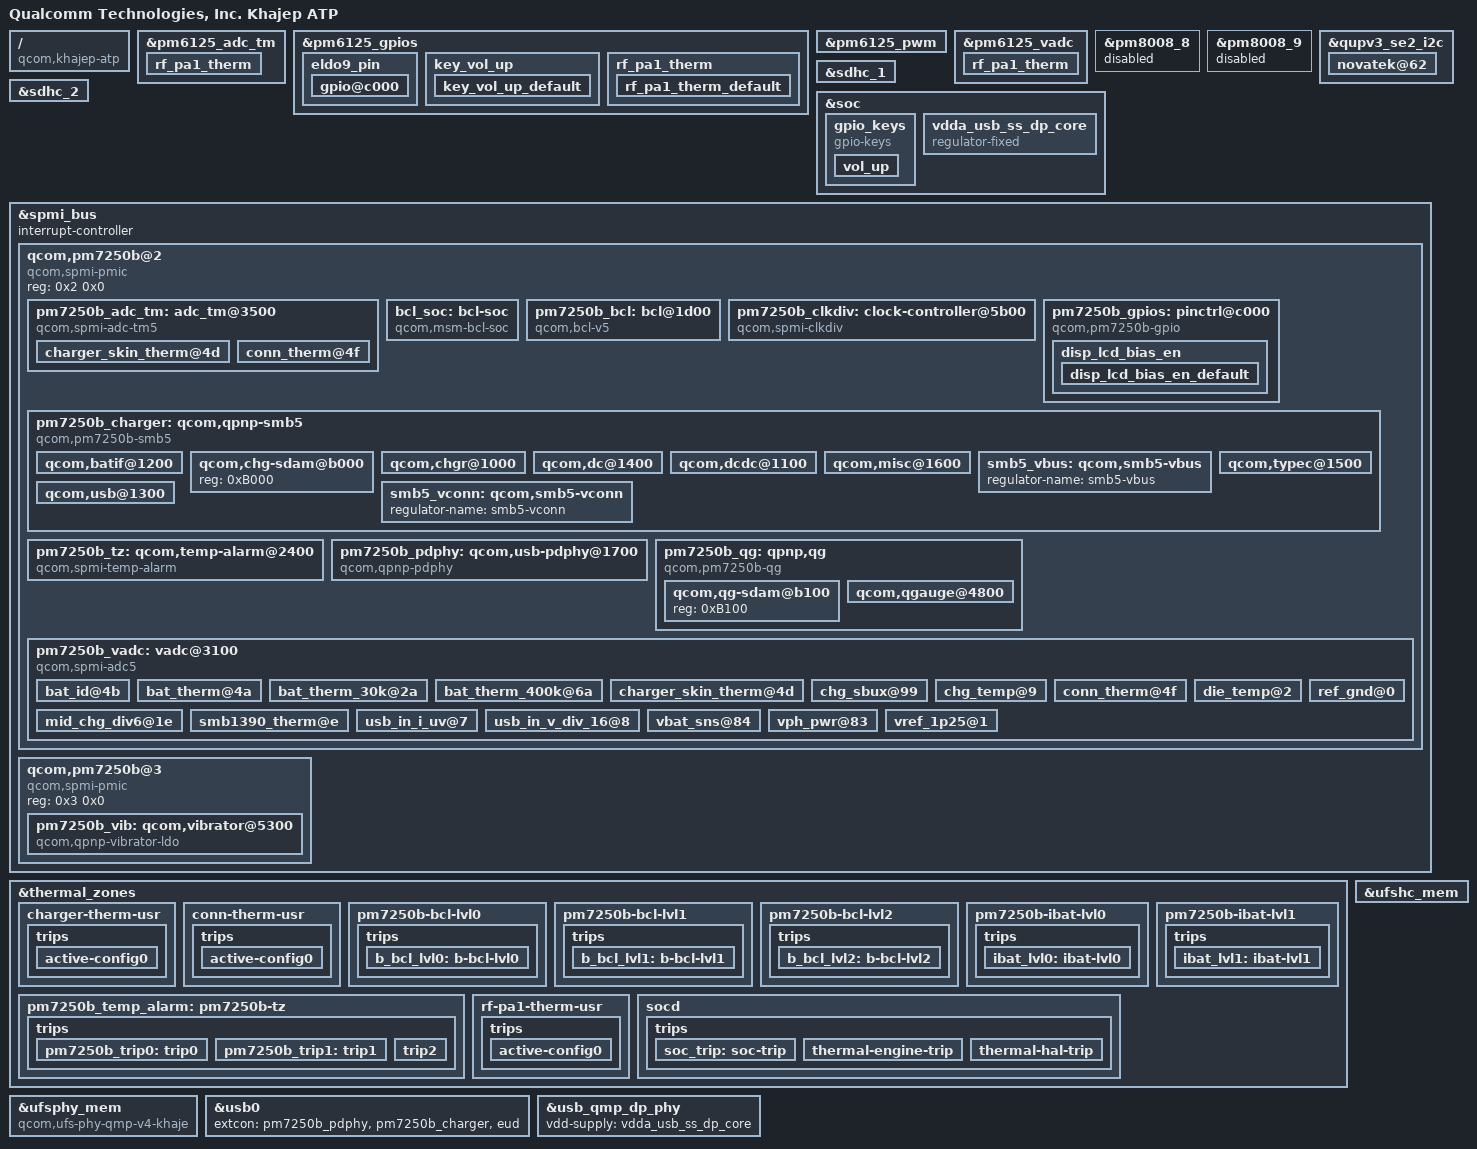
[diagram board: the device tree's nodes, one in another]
/dts-v1/;

/ {
    compatible = "qcom,khajep-atp", "qcom,khajep", "qcom,atp";
    model = "Qualcomm Technologies, Inc. Khajep ATP";
    qcom,board-id = <0x21 0x0>;
    qcom,msm-id = <0x231 0x10000>;
    qcom,pmic-id = <0x2D 0x2E 0x0 0x0>;
};

&pm6125_adc_tm {
    status = "ok";
    rf_pa1_therm {
        io-channels = <&pm6125_vadc 0x55>;
        qcom,hw-settle-time-us = <0xC8>;
        qcom,ratiometric;
        reg = <0x3>;
    };
};

&pm6125_gpios {
    eldo9_pin {
        gpio@c000 {
            bias-disable;
            function = "normal";
            output-high;
            pins = "gpio1";
            power-source = <0x0>;
            qcom,drive-strength = <0x2>;
        };
    };
    key_vol_up {
        key_vol_up_default: key_vol_up_default {
            bias-pull-up;
            function = "normal";
            input-enable;
            pins = "gpio5";
            power-source = <0x0>;
        };
    };
    rf_pa1_therm {
        rf_pa1_therm_default: rf_pa1_therm_default {
            bias-high-impedance;
            pins = "gpio7";
        };
    };
};

&pm6125_pwm {
    status = "okay";
};

&pm6125_vadc {
    pinctrl-0 = <&camera_therm_default &emmc_therm_default &rf_pa1_therm_default>;
    rf_pa1_therm {
        label = "rf_pa1_therm";
        qcom,hw-settle-time = <0xC8>;
        qcom,pre-scaling = <0x1 0x1>;
        qcom,ratiometric;
        reg = <0x55>;
    };
};

&pm8008_8 {
    status = "disabled";
};

&pm8008_9 {
    status = "disabled";
};

&qupv3_se2_i2c {
    status = "okay";
    novatek@62 {
        interrupt-parent = <&tlmm>;
        interrupts = <0x50 0x2008>;
        novatek,irq-gpio = <&tlmm 0x50 0x2008>;
        novatek,reset-gpio = <&tlmm 0x56 0x0>;
        pinctrl-0 = <&ts_int_active &ts_reset_active>;
        pinctrl-1 = <&ts_int_suspend &ts_reset_suspend>;
        pinctrl-2 = <&ts_release>;
        pinctrl-names = "pmx_ts_active", "pmx_ts_suspend", "pmx_ts_release";
        reg = <0x62>;
        status = "ok";
    };
};

&sdhc_1 {
    pinctrl-0 = <&sdc1_on>;
    pinctrl-1 = <&sdc1_off>;
    pinctrl-names = "active", "sleep";
    qcom,vdd-current-level = <0x0 0x8B290>;
    qcom,vdd-io-always-on;
    qcom,vdd-io-current-level = <0x0 0x4F588>;
    qcom,vdd-io-lpm-sup;
    qcom,vdd-io-voltage-level = <0x1B7740 0x1B7740>;
    qcom,vdd-voltage-level = <0x2D2A80 0x2D2A80>;
    status = "ok";
    vdd-io-supply = <&L11A>;
    vdd-supply = <&L24A>;
};

&sdhc_2 {
    cd-gpios = <&tlmm 0x58 0x1>;
    pinctrl-0 = <&sdc2_on>;
    pinctrl-1 = <&sdc2_off>;
    pinctrl-names = "active", "sleep";
    qcom,vdd-current-level = <0x0 0xC3500>;
    qcom,vdd-io-bias-current-level = <0x0 0x1770>;
    qcom,vdd-io-bias-voltage-level = <0x132A40 0x132A40>;
    qcom,vdd-io-current-level = <0x0 0x55F0>;
    qcom,vdd-io-voltage-level = <0x1B7740 0x2D2A80>;
    qcom,vdd-voltage-level = <0x2D2A80 0x2D2A80>;
    status = "ok";
    vdd-io-bias-supply = <&L7A>;
    vdd-io-supply = <&L5A>;
    vdd-supply = <&L22A>;
};

&soc {
    gpio_keys {
        compatible = "gpio-keys";
        label = "gpio-keys";
        pinctrl-0 = <&key_vol_up_default>;
        pinctrl-names = "default";
        vol_up {
            debounce-interval = <0xF>;
            gpio-key,wakeup;
            gpios = <&pm6125_gpios 0x5 0x1>;
            label = "volume_up";
            linux,can-disable;
            linux,code = <0x73>;
            linux,input-type = <0x1>;
        };
    };
    vdda_usb_ss_dp_core {
        compatible = "regulator-fixed";
        enable-active-high;
        gpio = <&pm6125_gpios 0x1 0x0>;
        pinctrl-0 = <&usb_eldo9>;
        pinctrl-names = "default";
        regulator-max-microvolt = <0xD6D80>;
        regulator-min-microvolt = <0xD6D80>;
        regulator-name = "vdd_supply";
    };
};

&spmi_bus {
    #address-cells = <0x2>;
    #interrupt-cells = <0x4>;
    #size-cells = <0x0>;
    interrupt-controller;
    qcom,pm7250b@2 {
        #address-cells = <0x1>;
        #size-cells = <0x0>;
        compatible = "qcom,spmi-pmic";
        reg = <0x2 0x0>;
        pm7250b_adc_tm: adc_tm@3500 {
            #address-cells = <0x1>;
            #size-cells = <0x0>;
            #thermal-sensor-cells = <0x1>;
            compatible = "qcom,spmi-adc-tm5";
            interrupt-names = "pm-adc-tm5";
            interrupts = <0x2 0x35 0x0 0x1>;
            reg = <0x3500>;
            status = "ok";
            charger_skin_therm@4d {
                io-channels = <&pm7250b_vadc 0x4D>;
                qcom,hw-settle-time-us = <0xC8>;
                qcom,ratiometric;
                reg = <0x0>;
            };
            conn_therm@4f {
                io-channels = <&pm7250b_vadc 0x4F>;
                qcom,hw-settle-time-us = <0xC8>;
                qcom,ratiometric;
                reg = <0x1>;
            };
        };
        bcl_soc: bcl-soc {
            #thermal-sensor-cells = <0x0>;
            compatible = "qcom,msm-bcl-soc";
        };
        pm7250b_bcl: bcl@1d00 {
            #thermal-sensor-cells = <0x1>;
            compatible = "qcom,bcl-v5";
            interrupt-names = "bcl-lvl0", "bcl-lvl1", "bcl-lvl2";
            interrupts = <0x2 0x1D 0x0 0x0 0x2 0x1D 0x1 0x0 0x2 0x1D 0x2 0x0>;
            reg = <0x1D00>;
        };
        pm7250b_clkdiv: clock-controller@5b00 {
            #clock-cells = <0x1>;
            assigned-clock-rates = <0x124F800>;
            assigned-clocks = <&pm7250b_clkdiv 0x1>;
            clock-names = "xo";
            clock-output-names = "pm7250b_div_clk1";
            clocks = <&rpmcc 0x0>;
            compatible = "qcom,spmi-clkdiv";
            qcom,num-clkdivs = <0x1>;
            reg = <0x5B00>;
        };
        pm7250b_gpios: pinctrl@c000 {
            #gpio-cells = <0x2>;
            #interrupt-cells = <0x2>;
            compatible = "qcom,pm7250b-gpio";
            gpio-controller;
            interrupt-controller;
            reg = <0xC000>;
            disp_lcd_bias_en {
                disp_lcd_bias_en_default: disp_lcd_bias_en_default {
                    bias-disable;
                    function = "func1";
                    input-disable;
                    output-enable;
                    pins = "gpio5";
                    power-source = <0x0>;
                    qcom,drive-strength = <0x2>;
                };
            };
        };
        pm7250b_charger: qcom,qpnp-smb5 {
            #address-cells = <0x1>;
            #cooling-cells = <0x2>;
            #size-cells = <0x1>;
            compatible = "qcom,pm7250b-smb5";
            depends-on-supply = <&pm7250b_vadc>;
            dpdm-supply = <&usb2_phy0>;
            io-channel-names = "usb_in_voltage", "usb_in_current", "chg_temp", "die_temp", "conn_temp", "sbux_res", "vph_voltage";
            io-channels = <&pm7250b_vadc 0x8 &pm7250b_vadc 0x7 &pm7250b_vadc 0x9 &pm7250b_vadc 0x6 &pm7250b_vadc 0x4F &pm7250b_vadc 0x99 &pm7250b_vadc 0x83>;
            qcom,auto-recharge-soc = <0x62>;
            qcom,batteryless-platform;
            qcom,charger-temp-max = <0x320>;
            qcom,hvdcp2-12v-max-icl-ua = <0x16E360>;
            qcom,hvdcp2-max-icl-ua = <0x1E8480>;
            qcom,sec-charger-config = <0x0>;
            qcom,step-charging-enable;
            qcom,suspend-input-on-debug-batt;
            qcom,sw-jeita-enable;
            qcom,thermal-mitigation = <0x5ACA30 0x5265C0 0x4C4B40 0x44AA20 0x3D0900 0x387520 0x3567E0 0x2DC6C0 0x2AB980 0x2625A0 0x1E8480 0x16E360 0xF4240 0xC3500 0x7A120 0x55730 0xC3500 0xC3500>;
            status = "ok";
            qcom,batif@1200 {
                interrupt-names = "bat-temp", "bat-ov", "bat-low", "bat-therm-or-id-missing", "bat-terminal-missing", "buck-oc", "vph-ov";
                interrupts = <0x2 0x12 0x0 0x1 0x2 0x12 0x2 0x3 0x2 0x12 0x3 0x3 0x2 0x12 0x4 0x3 0x2 0x12 0x5 0x3 0x2 0x12 0x6 0x3 0x2 0x12 0x7 0x3>;
                reg = <0x1200>;
            };
            qcom,chg-sdam@b000 {
                reg = <0xB000>;
            };
            qcom,chgr@1000 {
                interrupt-names = "chgr-error", "chg-state-change", "step-chg-state-change", "step-chg-soc-update-fail", "step-chg-soc-update-req", "fg-fvcal-qualified", "vph-alarm", "vph-drop-prechg";
                interrupts = <0x2 0x10 0x0 0x1 0x2 0x10 0x1 0x1 0x2 0x10 0x2 0x1 0x2 0x10 0x3 0x1 0x2 0x10 0x4 0x1 0x2 0x10 0x5 0x1 0x2 0x10 0x6 0x1 0x2 0x10 0x7 0x1>;
                reg = <0x1000>;
            };
            qcom,dc@1400 {
                interrupt-names = "dcin-vashdn", "dcin-uv", "dcin-ov", "dcin-plugin", "dcin-revi", "dcin-pon", "dcin-en";
                interrupts = <0x2 0x14 0x1 0x3 0x2 0x14 0x2 0x3 0x2 0x14 0x3 0x3 0x2 0x14 0x4 0x3 0x2 0x14 0x5 0x3 0x2 0x14 0x6 0x1 0x2 0x14 0x7 0x1>;
                reg = <0x1400>;
            };
            qcom,dcdc@1100 {
                interrupt-names = "otg-fail", "otg-oc-disable-sw", "otg-oc-hiccup", "bsm-active", "high-duty-cycle", "input-current-limiting", "concurrent-mode-disable", "switcher-power-ok";
                interrupts = <0x2 0x11 0x0 0x1 0x2 0x11 0x1 0x1 0x2 0x11 0x2 0x1 0x2 0x11 0x3 0x3 0x2 0x11 0x4 0x3 0x2 0x11 0x5 0x3 0x2 0x11 0x6 0x1 0x2 0x11 0x7 0x3>;
                reg = <0x1100>;
            };
            qcom,misc@1600 {
                interrupt-names = "wdog-snarl", "wdog-bark", "aicl-fail", "aicl-done", "smb-en", "imp-trigger", "temp-change", "temp-change-smb";
                interrupts = <0x2 0x16 0x0 0x1 0x2 0x16 0x1 0x1 0x2 0x16 0x2 0x1 0x2 0x16 0x3 0x1 0x2 0x16 0x4 0x3 0x2 0x16 0x5 0x1 0x2 0x16 0x6 0x1 0x2 0x16 0x7 0x1>;
                reg = <0x1600>;
            };
            smb5_vbus: qcom,smb5-vbus {
                regulator-name = "smb5-vbus";
            };
            smb5_vconn: qcom,smb5-vconn {
                regulator-name = "smb5-vconn";
            };
            qcom,typec@1500 {
                interrupt-names = "typec-or-rid-detect-change", "typec-vpd-detect", "typec-cc-state-change", "typec-vconn-oc", "typec-vbus-change", "typec-attach-detach", "typec-legacy-cable-detect", "typec-try-snk-src-detect";
                interrupts = <0x2 0x15 0x0 0x1 0x2 0x15 0x1 0x1 0x2 0x15 0x2 0x1 0x2 0x15 0x3 0x1 0x2 0x15 0x4 0x1 0x2 0x15 0x5 0x1 0x2 0x15 0x6 0x1 0x2 0x15 0x7 0x1>;
                reg = <0x1500>;
            };
            qcom,usb@1300 {
                interrupt-names = "usbin-collapse", "usbin-vashdn", "usbin-uv", "usbin-ov", "usbin-plugin", "usbin-revi-change", "usbin-src-change", "usbin-icl-change";
                interrupts = <0x2 0x13 0x0 0x3 0x2 0x13 0x1 0x3 0x2 0x13 0x2 0x3 0x2 0x13 0x3 0x3 0x2 0x13 0x4 0x3 0x2 0x13 0x5 0x3 0x2 0x13 0x6 0x1 0x2 0x13 0x7 0x1>;
                reg = <0x1300>;
            };
        };
        pm7250b_tz: qcom,temp-alarm@2400 {
            #thermal-sensor-cells = <0x0>;
            compatible = "qcom,spmi-temp-alarm";
            interrupts = <0x2 0x24 0x0 0x3>;
            io-channel-names = "thermal";
            io-channels = <&pm7250b_vadc 0x6>;
            qcom,temperature-threshold-set = <0x1>;
            reg = <0x2400>;
        };
        pm7250b_pdphy: qcom,usb-pdphy@1700 {
            #io-channel-cells = <0x1>;
            compatible = "qcom,qpnp-pdphy";
            interrupt-names = "sig-tx", "sig-rx", "msg-tx", "msg-rx", "msg-tx-failed", "msg-tx-discarded", "msg-rx-discarded", "fr-swap";
            interrupts = <0x2 0x17 0x0 0x1 0x2 0x17 0x1 0x1 0x2 0x17 0x2 0x1 0x2 0x17 0x3 0x1 0x2 0x17 0x4 0x1 0x2 0x17 0x5 0x1 0x2 0x17 0x6 0x1 0x2 0x17 0x7 0x1>;
            qcom,default-sink-caps = <0x1388 0xBB8 0x2328 0xBB8 0x2EE0 0x8CA>;
            reg = <0x1700>;
            vbus-supply = <&smb5_vbus>;
            vconn-supply = <&smb5_vconn>;
            vdd-pdphy-supply = <&L15A>;
        };
        pm7250b_qg: qpnp,qg {
            #address-cells = <0x1>;
            #size-cells = <0x1>;
            compatible = "qcom,pm7250b-qg";
            depends-on-supply = <&pm6125_rtc>;
            io-channel-names = "batt-therm", "batt-id";
            io-channels = <&pm7250b_vadc 0x2A &pm7250b_vadc 0x4B>;
            qcom,cl-feedback-on;
            qcom,hold-soc-while-full;
            qcom,linearize-soc;
            qcom,qg-iterm-ma = <0x96>;
            qcom,s3-entry-fifo-length = <0x2>;
            qcom,soc_decimal_rate = <0x0 0x20 0xA 0x1E 0x14 0x1C 0x1E 0x1C 0x28 0x1C 0x32 0x1C 0x3C 0x1C 0x46 0x1C 0x50 0x1C 0x5A 0x1A 0x5F 0xA 0x63 0x5>;
            qcom,vbatt-cutoff-mv = <0xC80>;
            qcom,vbatt-empty-cold-mv = <0xBB8>;
            qcom,vbatt-empty-mv = <0xBB8>;
            qcom,vbatt-low-cold-mv = <0xE74>;
            qcom,vbatt-low-mv = <0xCE4>;
            status = "ok";
            qcom,qg-sdam@b100 {
                reg = <0xB100>;
                status = "okay";
            };
            qcom,qgauge@4800 {
                interrupt-names = "qg-batt-missing", "qg-vbat-low", "qg-vbat-empty", "qg-fifo-done", "qg-good-ocv";
                interrupts = <0x2 0x48 0x0 0x3 0x2 0x48 0x1 0x3 0x2 0x48 0x2 0x1 0x2 0x48 0x3 0x1 0x2 0x48 0x4 0x1>;
                reg = <0x4800>;
                status = "okay";
            };
        };
        pm7250b_vadc: vadc@3100 {
            #address-cells = <0x1>;
            #io-channel-cells = <0x1>;
            #size-cells = <0x0>;
            compatible = "qcom,spmi-adc5";
            interrupt-names = "eoc-int-en-set";
            interrupts = <0x2 0x31 0x0 0x1>;
            io-channel-ranges;
            qcom,adc-vdd-reference = <0x753>;
            reg = <0x3100>;
            reg-names = "adc5-usr-base";
            bat_id@4b {
                label = "bat_id";
                qcom,hw-settle-time = <0xC8>;
                qcom,pre-scaling = <0x1 0x1>;
                qcom,ratiometric;
                reg = <0x4B>;
            };
            bat_therm@4a {
                label = "bat_therm";
                qcom,hw-settle-time = <0xC8>;
                qcom,pre-scaling = <0x1 0x1>;
                qcom,ratiometric;
                reg = <0x4A>;
            };
            bat_therm_30k@2a {
                label = "bat_therm_30k";
                qcom,hw-settle-time = <0xC8>;
                qcom,pre-scaling = <0x1 0x1>;
                qcom,ratiometric;
                reg = <0x2A>;
            };
            bat_therm_400k@6a {
                label = "bat_therm_400k";
                qcom,hw-settle-time = <0xC8>;
                qcom,pre-scaling = <0x1 0x1>;
                qcom,ratiometric;
                reg = <0x6A>;
            };
            charger_skin_therm@4d {
                label = "charger_skin_therm";
                qcom,hw-settle-time = <0xC8>;
                qcom,pre-scaling = <0x1 0x1>;
                qcom,ratiometric;
                reg = <0x4D>;
            };
            chg_sbux@99 {
                label = "chg_sbux";
                qcom,pre-scaling = <0x1 0x3>;
                reg = <0x99>;
            };
            chg_temp@9 {
                label = "chg_temp";
                qcom,pre-scaling = <0x1 0x1>;
                reg = <0x9>;
            };
            conn_therm@4f {
                label = "conn_therm";
                qcom,hw-settle-time = <0xC8>;
                qcom,pre-scaling = <0x1 0x1>;
                qcom,ratiometric;
                reg = <0x4F>;
            };
            die_temp@2 {
                label = "die_temp";
                qcom,pre-scaling = <0x1 0x1>;
                reg = <0x6>;
            };
            mid_chg_div6@1e {
                label = "chg_mid";
                qcom,pre-scaling = <0x1 0x6>;
                reg = <0x1E>;
            };
            ref_gnd@0 {
                label = "ref_gnd";
                qcom,pre-scaling = <0x1 0x1>;
                reg = <0x0>;
            };
            smb1390_therm@e {
                label = "smb1390_therm";
                qcom,hw-settle-time = <0xC8>;
                qcom,pre-scaling = <0x1 0x1>;
                reg = <0xE>;
            };
            usb_in_i_uv@7 {
                label = "usb_in_i_uv";
                qcom,pre-scaling = <0x1 0x1>;
                reg = <0x7>;
            };
            usb_in_v_div_16@8 {
                label = "usb_in_v_div_16";
                qcom,pre-scaling = <0x1 0x10>;
                reg = <0x8>;
            };
            vbat_sns@84 {
                label = "vbat_sns";
                qcom,pre-scaling = <0x1 0x3>;
                reg = <0x84>;
            };
            vph_pwr@83 {
                label = "vph_pwr";
                qcom,pre-scaling = <0x1 0x3>;
                reg = <0x83>;
            };
            vref_1p25@1 {
                label = "vref_1p25";
                qcom,pre-scaling = <0x1 0x1>;
                reg = <0x1>;
            };
        };
    };
    qcom,pm7250b@3 {
        #address-cells = <0x1>;
        #size-cells = <0x0>;
        compatible = "qcom,spmi-pmic";
        reg = <0x3 0x0>;
        pm7250b_vib: qcom,vibrator@5300 {
            compatible = "qcom,qpnp-vibrator-ldo";
            qcom,disable-overdrive;
            qcom,vib-ldo-volt-uv = <0x2DC6C0>;
            reg = <0x5300>;
        };
    };
};

&thermal_zones {
    charger-therm-usr {
        polling-delay = <0x0>;
        polling-delay-passive = <0x0>;
        thermal-governor = "user_space";
        thermal-sensors = <&pm7250b_adc_tm 0x0>;
        wake-capable-sensor;
        trips {
            active-config0 {
                hysteresis = <0x3E8>;
                temperature = <0x1E848>;
                type = "passive";
            };
        };
    };
    conn-therm-usr {
        polling-delay = <0x0>;
        polling-delay-passive = <0x0>;
        thermal-governor = "user_space";
        thermal-sensors = <&pm7250b_adc_tm 0x1>;
        wake-capable-sensor;
        trips {
            active-config0 {
                hysteresis = <0x3E8>;
                temperature = <0x1E848>;
                type = "passive";
            };
        };
    };
    pm7250b-bcl-lvl0 {
        polling-delay = <0x0>;
        polling-delay-passive = <0x64>;
        thermal-sensors = <&pm7250b_bcl 0x5>;
        trips {
            b_bcl_lvl0: b-bcl-lvl0 {
                hysteresis = <0x1>;
                temperature = <0x1>;
                type = "passive";
            };
        };
    };
    pm7250b-bcl-lvl1 {
        polling-delay = <0x0>;
        polling-delay-passive = <0x64>;
        thermal-sensors = <&pm7250b_bcl 0x6>;
        trips {
            b_bcl_lvl1: b-bcl-lvl1 {
                hysteresis = <0x1>;
                temperature = <0x1>;
                type = "passive";
            };
        };
    };
    pm7250b-bcl-lvl2 {
        polling-delay = <0x0>;
        polling-delay-passive = <0x64>;
        thermal-sensors = <&pm7250b_bcl 0x7>;
        trips {
            b_bcl_lvl2: b-bcl-lvl2 {
                hysteresis = <0x1>;
                temperature = <0x1>;
                type = "passive";
            };
        };
    };
    pm7250b-ibat-lvl0 {
        polling-delay = <0x0>;
        polling-delay-passive = <0x0>;
        thermal-sensors = <&pm7250b_bcl 0x0>;
        trips {
            ibat_lvl0: ibat-lvl0 {
                hysteresis = <0xC8>;
                temperature = <0x157C>;
                type = "passive";
            };
        };
    };
    pm7250b-ibat-lvl1 {
        polling-delay = <0x0>;
        polling-delay-passive = <0x0>;
        thermal-sensors = <&pm7250b_bcl 0x1>;
        trips {
            ibat_lvl1: ibat-lvl1 {
                hysteresis = <0xC8>;
                temperature = <0x1770>;
                type = "passive";
            };
        };
    };
    pm7250b_temp_alarm: pm7250b-tz {
        polling-delay = <0x0>;
        polling-delay-passive = <0x64>;
        thermal-sensors = <&pm7250b_tz>;
        trips {
            pm7250b_trip0: trip0 {
                hysteresis = <0x0>;
                temperature = <0x17318>;
                type = "passive";
            };
            pm7250b_trip1: trip1 {
                hysteresis = <0x0>;
                temperature = <0x1C138>;
                type = "passive";
            };
            trip2 {
                hysteresis = <0x0>;
                temperature = <0x23668>;
                type = "passive";
            };
        };
    };
    rf-pa1-therm-usr {
        polling-delay = <0x0>;
        polling-delay-passive = <0x0>;
        thermal-governor = "user_space";
        thermal-sensors = <&pm6125_adc_tm 0x3>;
        wake-capable-sensor;
        trips {
            active-config0 {
                hysteresis = <0x3E8>;
                temperature = <0x1E848>;
                type = "passive";
            };
        };
    };
    socd {
        polling-delay = <0x0>;
        polling-delay-passive = <0x64>;
        trips {
            soc_trip: soc-trip {
                hysteresis = <0x0>;
                temperature = <0x5A>;
                type = "passive";
            };
            thermal-engine-trip {
                hysteresis = <0x0>;
                temperature = <0x64>;
                type = "passive";
            };
            thermal-hal-trip {
                hysteresis = <0x0>;
                temperature = <0x64>;
                type = "passive";
            };
        };
    };
};

&ufshc_mem {
    qcom,vddp-ref-clk-max-microamp = <0x64>;
    qcom,vddp-ref-clk-supply = <&L18A>;
    reset-gpios = <&tlmm 0x71 0x1>;
    reset-names = "rst";
    resets = <&gcc 0x4>;
    status = "ok";
    vcc-max-microamp = "\f5";
    vcc-supply = <&L24A>;
    vccq2-max-microamp = "\f5";
    vccq2-supply = <&L11A>;
    vdd-hba-fixed-regulator;
    vdd-hba-supply = <&gcc_ufs_phy_gdsc>;
};

&ufsphy_mem {
    compatible = "qcom,ufs-phy-qmp-v4-khaje";
    status = "ok";
    vdda-phy-max-microamp = <0x14EC4>;
    vdda-phy-supply = <&L4A>;
    vdda-pll-max-microamp = <0x477C>;
    vdda-pll-supply = <&L18A>;
};

&usb0 {
    extcon = <&pm7250b_pdphy &pm7250b_charger &eud>;
};

&usb_qmp_dp_phy {
    vdd-supply = <&vdda_usb_ss_dp_core>;
};

